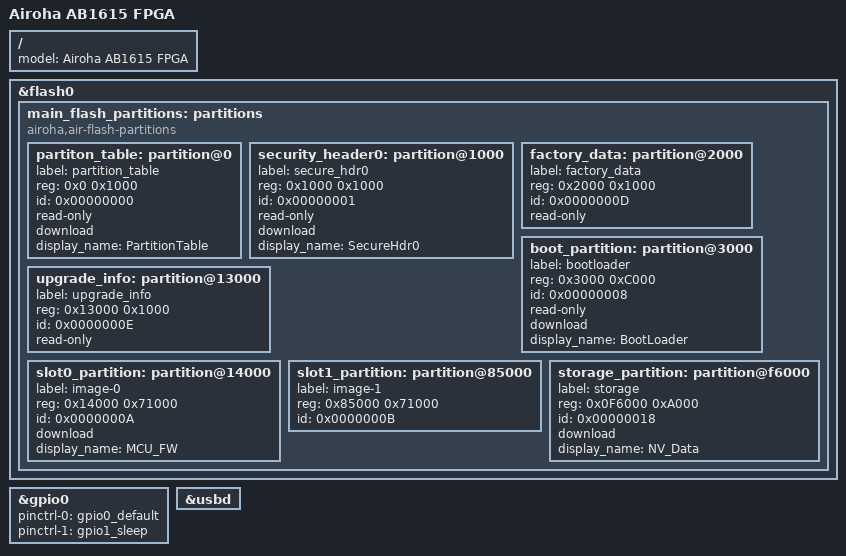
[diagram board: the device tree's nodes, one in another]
/* Copyright Statement:
 *
 * (C) 2025  Airoha Technology Corp. All rights reserved.
 *
 * This software/firmware and related documentation ("Airoha Software") are
 * protected under relevant copyright laws. The information contained herein
 * is confidential and proprietary to Airoha Technology Corp. ("Airoha") and/or its licensors.
 * Without the prior written permission of Airoha and/or its licensors,
 * any reproduction, modification, use or disclosure of Airoha Software,
 * and information contained herein, in whole or in part, shall be strictly prohibited.
 * You may only use, reproduce, modify, or distribute (as applicable) Airoha Software
 * if you have agreed to and been bound by the applicable license agreement with
 * Airoha ("License Agreement") and been granted explicit permission to do so within
 * the License Agreement ("Permitted User").  If you are not a Permitted User,
 * please cease any access or use of Airoha Software immediately.
 * BY OPENING THIS FILE, RECEIVER HEREBY UNEQUIVOCALLY ACKNOWLEDGES AND AGREES
 * THAT THE SOFTWARE/FIRMWARE AND ITS DOCUMENTATIONS ("AIROHA SOFTWARE")
 * RECEIVED FROM AIROHA AND/OR ITS REPRESENTATIVES ARE PROVIDED
 * TO RECEIVER ON AN "AS-IS" BASIS ONLY. AIROHA EXPRESSLY DISCLAIMS ANY AND ALL
 * WARRANTIES, EXPRESS OR IMPLIED, INCLUDING BUT NOT LIMITED TO THE IMPLIED WARRANTIES OF
 * MERCHANTABILITY, FITNESS FOR A PARTICULAR PURPOSE OR NONINFRINGEMENT.
 * NEITHER DOES AIROHA PROVIDE ANY WARRANTY WHATSOEVER WITH RESPECT TO THE
 * SOFTWARE OF ANY THIRD PARTY WHICH MAY BE USED BY, INCORPORATED IN, OR
 * SUPPLIED WITH AIROHA SOFTWARE, AND RECEIVER AGREES TO LOOK ONLY TO SUCH
 * THIRD PARTY FOR ANY WARRANTY CLAIM RELATING THERETO. RECEIVER EXPRESSLY ACKNOWLEDGES
 * THAT IT IS RECEIVER'S SOLE RESPONSIBILITY TO OBTAIN FROM ANY THIRD PARTY ALL PROPER LICENSES
 * CONTAINED IN AIROHA SOFTWARE. AIROHA SHALL ALSO NOT BE RESPONSIBLE FOR ANY AIROHA
 * SOFTWARE RELEASES MADE TO RECEIVER'S SPECIFICATION OR TO CONFORM TO A PARTICULAR
 * STANDARD OR OPEN FORUM. RECEIVER'S SOLE AND EXCLUSIVE REMEDY AND AIROHA'S ENTIRE AND
 * CUMULATIVE LIABILITY WITH RESPECT TO AIROHA SOFTWARE RELEASED HEREUNDER WILL BE,
 * AT AIROHA'S OPTION, TO REVISE OR REPLACE AIROHA SOFTWARE AT ISSUE,
 * OR REFUND ANY SOFTWARE LICENSE FEES OR SERVICE CHARGE PAID BY RECEIVER TO
 * AIROHA FOR SUCH AIROHA SOFTWARE AT ISSUE.
 */

/* SPDX-License-Identifier: Apache-2.0 */

/dts-v1/;

/* airoha/mcu/dts/arm/airoha/ab161x\/ab161x_common\.dtsi */
#include <airoha/ab161x/ab161x_common.dtsi>
#include "ab1615_fpga-pinctrl.dtsi"

/ {
    model = "Airoha AB1615 FPGA";
};

&flash0 {
    main_flash_partitions: partitions {
        compatible ="airoha,air-flash-partitions", "fixed-partitions";
        #address-cells = <1>;
        #size-cells = <1>;

        /* The @ symbol is followed by the offset of the flash device */
        partiton_table: partition@0 {
            label = "partition_table";
            reg = <0x0 0x1000>;
            id = <0x00000000>;
            read-only;
            download;
            display_name = "PartitionTable";
        };
        security_header0: partition@1000 {
            label = "secure_hdr0";
            reg = <0x1000 0x1000>;
            id = <0x00000001>;
            read-only;
            download;
            display_name = "SecureHdr0";
        };
        factory_data: partition@2000 {
            label = "factory_data";
            /* offset of flash device, partition size */
            reg = <0x2000 0x1000>;
            id = <0x0000000D>;
            read-only;
        };
        boot_partition: partition@3000 {
            label = "bootloader";
            /* offset of flash device, partition size */
            reg = <0x3000 0xC000>;
            id = <0x00000008>;
            read-only;
            download;
            display_name = "BootLoader";
        };
        upgrade_info: partition@13000 {
            label = "upgrade_info";
            /* offset of flash device, partition size */
            reg = <0x13000 0x1000>;
            id = <0x0000000E>;
            read-only;
        };
        slot0_partition: partition@14000 {
            /* Use the image-0 name to be compatible with the need to use MCUboot and
             * MCUboot needs to sign the first image of main application.
             * For more details please see zephyr/scripts/west_commands/sign.py.
             */
            label = "image-0";
            reg = <0x14000 0x71000>;
            id = <0x0000000A>;
            download;
            display_name = "MCU_FW";
        };
        slot1_partition: partition@85000 {
            label = "image-1";
            reg = <0x85000 0x71000>;
            id = <0x0000000B>;
        };
        storage_partition: partition@f6000 {
            label = "storage";
            reg = <0x0F6000 0xA000>;
            id = <0x00000018>;
            download;
            display_name = "NV_Data";
        };
    };
};
&gpio0 {
    pinctrl-0 = <&gpio0_default>;
    pinctrl-1 = <&gpio1_sleep>;
    pinctrl-names = "default","sleep";
};
zephyr_udc0: &usbd {
    status = "okay";
};
